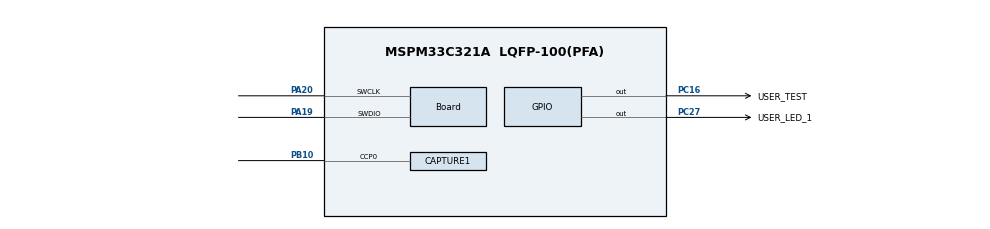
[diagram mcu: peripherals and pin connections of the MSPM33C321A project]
//@cliArgs --device "MSPM33C321A" --package "LQFP-100(PFA)" --part "Default"
//@v2CliArgs --device "MSPM33C321A" --package "LQFP-100(PFA)"
// @cliArgs --board /ti/boards/LP_MSPM33C321A --rtos nortos


/**
 * Import the modules used in this configuration.
 */
const CAPTURE       = scripting.addModule("/ti/driverlib/CAPTURE", {}, false);
const CAPTURE1      = CAPTURE.addInstance();
const GPIO          = scripting.addModule("/ti/driverlib/GPIO", {}, false);
const GPIO1         = GPIO.addInstance();
const SYSCTL        = scripting.addModule("/ti/driverlib/SYSCTL");
const ProjectConfig = scripting.addModule("/ti/project_config/ProjectConfig");

/**
 * Write custom configuration values to the imported modules.
 */
CAPTURE1.$name                      = "CAPTURE_0";
CAPTURE1.timerClkSrc                = "LFCLK";
CAPTURE1.timerClkPrescale           = 256;
CAPTURE1.interrupts                 = ["CC0_DN"];
CAPTURE1.timerPeriod                = "15.36 s";
CAPTURE1.peripheral.$assign         = "TIMG4_0";
CAPTURE1.peripheral.ccp0Pin.$assign = "PB10";
CAPTURE1.ccp0PinConfig.$name        = "ti_driverlib_gpio_GPIOPinGeneric0";

const Board                       = scripting.addModule("/ti/driverlib/Board", {}, false);
Board.peripheral.$assign          = "DEBUGSS";
Board.peripheral.swclkPin.$assign = "PA20";
Board.peripheral.swdioPin.$assign = "PA19";

GPIO1.$name                                 = "GPIO_LEDS";
GPIO1.associatedPins.create(2);
GPIO1.associatedPins[0].launchPadShortcut   = "LED2GreenEn";
GPIO1.associatedPins[0].$name               = "USER_LED_1";
GPIO1.associatedPins[0].pin.$assign         = "PC27";
GPIO1.associatedPins[1].$name               = "USER_TEST";
GPIO1.associatedPins[1].assignedPort        = "PORTC";
GPIO1.associatedPins[1].assignedPortSegment = "Upper";
GPIO1.associatedPins[1].assignedPin         = "16";
GPIO1.associatedPins[1].pin.$assign         = "PC16";

SYSCTL.forceDefaultClkConfig = true;
SYSCTL.peripheral.$assign    = "SYSCTL";

ProjectConfig.genLinker          = true;
ProjectConfig.genStartup         = true;
ProjectConfig.genOpts            = true;
ProjectConfig.genLibs            = true;
ProjectConfig.migrationCondition = true;
